# CY8C5888LTI_LP097 register map
File version: 0.1
Registers are 8-bit, read-write, no defined reset value unless marked. A register's access mark holds for its fields unless they carry their own. Offsets are from the block's base; [hi:lo] are bit positions; {n}, {i} and the like mark numbered series; 'fields as' and 'values as' point back to an identical list.

## Opamp_Throttle
Base 0x00000000
0x400043A4 PM_ACT_CFG4 — Active Power Mode Configuration Register 4
  [3:0] EN_OPAMP — Enables subsystems during active power mode
    0=Blk_0 (Enables analog linear output buffer for Opamp block 0); 2=Blk_1 (Enables analog linear output buffer for Opamp block 1); 4=Blk_2 (Enables analog linear output buffer for Opamp block 2); 8=Blk_3 (Enables analog linear output buffer for Opamp block 3)
0x400043B4 PM_STBY_CFG4 — Standby Power Mode Configuration Register 4
  [3:0] EN_OPAMP — Enables subsystems during standby power mode
    values as PM_ACT_CFG4.EN_OPAMP
0x40004626 OPAMP__TR0 — Analog Output Buffer Trim Register 0
  [4:0] offset_trim — Offset Trim: 420uV typical step size; +/- 6.8mV offset trimmable range
0x40004627 OPAMP__TR1 — Analog Output Buffer Trim Register 1
0x4000585E OPAMP__CR — Analog Output Buffer Configuration Register
  [1:0] pwr_mode — Power Mode
    0=Default_Fast (Default Power mode Fast); 1=Slow (Power Mode Slow); 2=Medium (Power Mode Medium); 3=Fast (Power Mode Fast)
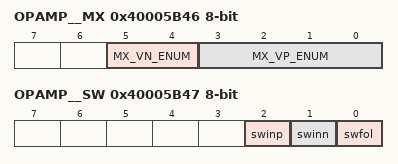
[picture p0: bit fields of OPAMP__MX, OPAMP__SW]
0x40005B46 OPAMP__MX — Analog Buffer Input Selection Register
  [5:4] MX_VN_ENUM — MUX select VN (Negative terminal input)
    0=OPAMP0_MX_VN_DEFAULT (Default - Not Connected (NC)); 1=OPAMP0_MX_VN_AG4 (MUX Selection AGL(4)); 2=OPAMP0_MX_VN_AG6 (MUX Selection AGL(6)); 3=OPAMP0_MX_VN_0x3 (Reserved (NC))
  [3:0] MX_VP_ENUM — MUX select VP (Positive terminal input)
    0=OPAMP0_MX_VP_DEFAULT (Default - Not Connected (NC)); {v}=OPAMP0_MX_VP_AG{v+3} (MUX Selection AGL({v+3})) (v=1..4); {v}=OPAMP0_MX_VP_ABUS{v-5} (MUX Selection ABUSL({v-5})) (v=5..8); 9=OPAMP0_MX_VP_VREF (MUX Selection: OPAMP Voltage Reference); {v}=OPAMP0_MX_VP_H_{0x0+v} (Reserved (NC)) (v=10..15)
0x40005B47 OPAMP__SW — Analog Buffer Routing Switch Register
  [2] swinp — Switch Enable Positive Input
  [1] swinn — Switch Enable Negative Input
  [0] swfol — Switch Enable Follow

## CMG_UART — UART
Base 0x00000000
0x4000644F TX_CMG_UART_TX_DATA — TX Data Register
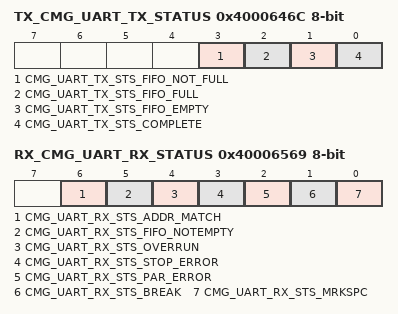
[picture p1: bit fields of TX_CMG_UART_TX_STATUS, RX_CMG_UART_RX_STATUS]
0x4000646C TX_CMG_UART_TX_STATUS — TX status register
  [3] CMG_UART_TX_STS_FIFO_NOT_FULL ro, [2] CMG_UART_TX_STS_FIFO_FULL ro, [1] CMG_UART_TX_STS_FIFO_EMPTY ro, [0] CMG_UART_TX_STS_COMPLETE ro
0x40006529 RX_CMG_UART_RX_ADDRESS1 — RX Address1 Register
0x40006539 RX_CMG_UART_RX_ADDRESS2 — RX Address2 Register
0x40006549 RX_CMG_UART_RX_DATA — RX Data Register
0x40006569 RX_CMG_UART_RX_STATUS — RX status register
  [6] CMG_UART_RX_STS_ADDR_MATCH ro, [5] CMG_UART_RX_STS_FIFO_NOTEMPTY ro, [4] CMG_UART_RX_STS_OVERRUN ro, [3] CMG_UART_RX_STS_STOP_ERROR ro, [2] CMG_UART_RX_STS_PAR_ERROR ro, [1] CMG_UART_RX_STS_BREAK ro, [0] CMG_UART_RX_STS_MRKSPC ro

## QuadDec_1
Base 0x00000000
0x4000640C QuadDec_1_Cnt16_COUNTER 16-bit — Counter value
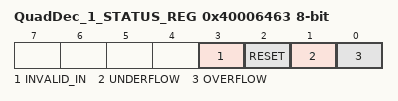
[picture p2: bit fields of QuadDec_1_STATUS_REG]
0x40006463 QuadDec_1_STATUS_REG — Quadrature Decoder Status Register
  [3] INVALID_IN ro — Invalid state transition on the A and B inputs
  [2] RESET ro — Counter Reset due index
  [1] UNDERFLOW ro — Counter underflow
  [0] OVERFLOW ro — Counter overflow

## QuadDec_1_Cnt16
Base 0x00000000; alternate view of QuadDec_1
0x4000640C QuadDec_1_Cnt16_COUNTER 16-bit — UDB.A0 - Current Counter Value
0x4000642C QuadDec_1_Cnt16_PERIOD 16-bit — UDB.D0 - Assigned Period
0x4000643C QuadDec_1_Cnt16_COMPARE 16-bit — UDB.D1 - Assigned Compare Value
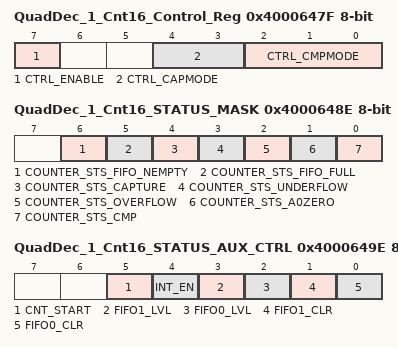
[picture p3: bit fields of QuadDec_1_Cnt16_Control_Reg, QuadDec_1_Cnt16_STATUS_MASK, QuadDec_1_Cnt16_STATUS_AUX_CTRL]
0x4000647F QuadDec_1_Cnt16_Control_Reg — UDB Control Register - Assigned Control Register Value
  [7] CTRL_ENABLE — Enable Counter
  [4:3] CTRL_CAPMODE — Capture mode
  [2:0] CTRL_CMPMODE — Compare mode
0x4000648E QuadDec_1_Cnt16_STATUS_MASK — UDB Status bits Interrupt Mask Enable Register
  [6] COUNTER_STS_FIFO_NEMPTY — FIFO Not Empty Status
  [5] COUNTER_STS_FIFO_FULL — FIFO Full Status
  [4] COUNTER_STS_CAPTURE — Capture Status
  [3] COUNTER_STS_UNDERFLOW — Underflow status
  [2] COUNTER_STS_OVERFLOW — Overflow status
  [1] COUNTER_STS_A0ZERO — A0 Zero ouput status
  [0] COUNTER_STS_CMP — Compare output status
0x4000649E QuadDec_1_Cnt16_STATUS_AUX_CTRL — UDB Auxilliary Control Register
  [5] CNT_START — FIFO0 clear
    0=E_CNT_START0 (Disable counter); 1=E_CNT_START1 (Enable counter)
  [4] INT_EN
    0=E_INT_EN0 (Interrupt disabled); 1=E_INT_EN1 (Interrupt enabled)
  [3] FIFO1_LVL — FIFO level
    0=E_FIFO_LVL_0 (FIFO LVL: input mode: FIFO not full; output mode: FIFO not empty); 1=E_FIFO_LVL_1 (FIFO LVL: input mode: FIFO at least 1/2 empty; output mode: FIFO at least 1/2 full)
  [2] FIFO0_LVL — FIFO level
    values as FIFO1_LVL
  [1] FIFO1_CLR — FIFO1 clear
    0=E_FIFO_CLR_0 (Normal FIFO operation); 1=E_FIFO_CLR_1 (Clear FIFO state)
  [0] FIFO0_CLR — FIFO0 clear
    values as FIFO1_CLR
